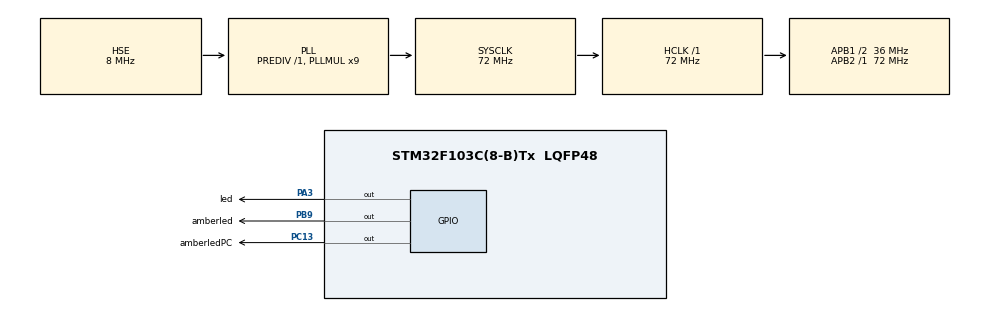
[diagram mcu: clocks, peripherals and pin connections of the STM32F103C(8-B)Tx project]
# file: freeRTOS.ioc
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FREERTOS.CountingSemaphores01=slotSemp,5,Dynamic,NULL;itemSemp,5,Dynamic,NULL
FREERTOS.Mutexes01=qMutex;mailMutex
FREERTOS.Queues01=itemQueue,5,int,NULL,Dynamic,NULL,NULL
FREERTOS.Tasks01=defaultTask,0,128,StartDefaultTask,Default,NULL,Dynamic,NULL,NULL;producer,-3,128,StartProducer,Default,NULL,Dynamic,NULL,NULL;consumer,-3,128,StartConsumer,Default,NULL,Dynamic,NULL,NULL
FREERTOS.configTOTAL_HEAP_SIZE=6144
FREERTOS.configUSE_COUNTING_SEMAPHORES=1
FREERTOS.configUSE_RECURSIVE_MUTEXES=1
FREERTOS.configUSE_TIMERS=1
Mcu.Family=STM32F1
Mcu.Name=STM32F103C(8-B)Tx
Mcu.Package=LQFP48
Mcu.UserConstants=Timer1_Counter,10000;TIM_RELOAD,10000;queueSize,10
NVIC.PriorityGroup=NVIC_PRIORITYGROUP_4
NVIC.TIM3_IRQn=true\:0\:0\:false\:false\:true\:false
NVIC.TimeBase=TIM3_IRQn
NVIC.TimeBaseIP=TIM3
PA13.Mode=Serial_Wire
PA13.Signal=SYS_JTMS-SWDIO
PA14.Mode=Serial_Wire
PA14.Signal=SYS_JTCK-SWCLK
PA3.GPIO_Label=led
PA3.PinState=GPIO_PIN_RESET
PA3.Signal=GPIO_Output
PB9.GPIO_Label=amberled
PB9.GPIO_Speed=GPIO_SPEED_FREQ_HIGH
PB9.PinState=GPIO_PIN_RESET
PB9.Signal=GPIO_Output
PC13-TAMPER-RTC.GPIO_Label=amberledPC
PC13-TAMPER-RTC.Signal=GPIO_Output
PD0-OSC_IN.Mode=HSE-External-Oscillator
PD0-OSC_IN.Signal=RCC_OSC_IN
PD1-OSC_OUT.Mode=HSE-External-Oscillator
PD1-OSC_OUT.Signal=RCC_OSC_OUT
ProjectManager.HeapSize=0x200
ProjectManager.StackSize=0x400
ProjectManager.TargetToolchain=SW4STM32
RCC.AHBFreq_Value=72000000
RCC.APB1CLKDivider=RCC_HCLK_DIV2
RCC.APB1Freq_Value=36000000
RCC.APB1TimFreq_Value=72000000
RCC.APB2Freq_Value=72000000
RCC.APB2TimFreq_Value=72000000
RCC.HCLKFreq_Value=72000000
RCC.PLLMUL=RCC_PLL_MUL9
RCC.PLLSourceVirtual=RCC_PLLSOURCE_HSE
RCC.SYSCLKFreq_VALUE=72000000
RCC.SYSCLKSource=RCC_SYSCLKSOURCE_PLLCLK
RCC.USBFreq_Value=72000000
VP_FREERTOS_VS_ENABLE.Mode=Enabled
VP_SYS_VS_tim3.Mode=TIM3
board=freeRTOS

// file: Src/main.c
/**
  ******************************************************************************
  * File Name          : main.c
  * Description        : Main program body
  ******************************************************************************
  * This notice applies to any and all portions of this file
  * that are not between comment pairs USER CODE BEGIN and
  * USER CODE END. Other portions of this file, whether
  * inserted by the user or by software development tools
  * are owned by their respective copyright owners.
  *
  * Copyright (c) 2017 STMicroelectronics International N.V.
  * All rights reserved.
  *
  * Redistribution and use in source and binary forms, with or without
  * modification, are permitted, provided that the following conditions are met:
  *
  * 1. Redistribution of source code must retain the above copyright notice,
  *    this list of conditions and the following disclaimer.
  * 2. Redistributions in binary form must reproduce the above copyright notice,
  *    this list of conditions and the following disclaimer in the documentation
  *    and/or other materials provided with the distribution.
  * 3. Neither the name of STMicroelectronics nor the names of other
  *    contributors to this software may be used to endorse or promote products
  *    derived from this software without specific written permission.
  * 4. This software, including modifications and/or derivative works of this
  *    software, must execute solely and exclusively on microcontroller or
  *    microprocessor devices manufactured by or for STMicroelectronics.
  * 5. Redistribution and use of this software other than as permitted under
  *    this license is void and will automatically terminate your rights under
  *    this license.
  *
  * THIS SOFTWARE IS PROVIDED BY STMICROELECTRONICS AND CONTRIBUTORS "AS IS"
  * AND ANY EXPRESS, IMPLIED OR STATUTORY WARRANTIES, INCLUDING, BUT NOT
  * LIMITED TO, THE IMPLIED WARRANTIES OF MERCHANTABILITY, FITNESS FOR A
  * PARTICULAR PURPOSE AND NON-INFRINGEMENT OF THIRD PARTY INTELLECTUAL PROPERTY
  * RIGHTS ARE DISCLAIMED TO THE FULLEST EXTENT PERMITTED BY LAW. IN NO EVENT
  * SHALL STMICROELECTRONICS OR CONTRIBUTORS BE LIABLE FOR ANY DIRECT, INDIRECT,
  * INCIDENTAL, SPECIAL, EXEMPLARY, OR CONSEQUENTIAL DAMAGES (INCLUDING, BUT NOT
  * LIMITED TO, PROCUREMENT OF SUBSTITUTE GOODS OR SERVICES; LOSS OF USE, DATA,
  * OR PROFITS; OR BUSINESS INTERRUPTION) HOWEVER CAUSED AND ON ANY THEORY OF
  * LIABILITY, WHETHER IN CONTRACT, STRICT LIABILITY, OR TORT (INCLUDING
  * NEGLIGENCE OR OTHERWISE) ARISING IN ANY WAY OUT OF THE USE OF THIS SOFTWARE,
  * EVEN IF ADVISED OF THE POSSIBILITY OF SUCH DAMAGE.
  *
  ******************************************************************************
  */
#include "main.h"
#include "stm32f1xx_hal.h"
#include "cmsis_os.h"

/* USER CODE BEGIN Includes */
#include <stdio.h>
/* USER CODE END Includes */

osThreadId defaultTaskHandle;
osThreadId producerHandle;
osThreadId consumerHandle;
osMessageQId itemQueueHandle;
osMutexId qMutexHandle;
osMutexId mailMutexHandle;
osSemaphoreId slotSempHandle;
osSemaphoreId itemSempHandle;

/* USER CODE BEGIN PV */
/* Private variables ---------------------------------------------------------*/
static uint32_t obj = 5;
osMailQId mailBoxHandler;

/* USER CODE END PV */

void SystemClock_Config(void);
static void MX_GPIO_Init(void);
extern void initialise_monitor_handles();
void StartDefaultTask(void const * argument);
void StartProducer(void const * argument);
void StartConsumer(void const * argument);

/* USER CODE BEGIN PFP */
/* Private function prototypes -----------------------------------------------*/
extern void initialise_monitor_handles(void);
/* USER CODE END PFP */

/* USER CODE BEGIN 0 */
typedef struct mail mailData;
struct mail{
	int data;
	char *name;
};
/* USER CODE END 0 */

int main(void)
{

  /* USER CODE BEGIN 1 */
  initialise_monitor_handles();

  /* USER CODE END 1 */

  /* MCU Configuration----------------------------------------------------------*/

  /* Reset of all peripherals, Initializes the Flash interface and the Systick. */
	HAL_Init();

  /* Configure the system clock */
  SystemClock_Config();

  /* Initialize all configured peripherals */
  MX_GPIO_Init();

  /* USER CODE BEGIN 2 */
  printf("Hello,Jason!\n");
  /* USER CODE END 2 */

  /* Create the mutex(es) */
  /* definition and creation of qMutex */
  osMutexDef(qMutex);
  qMutexHandle = osMutexCreate(osMutex(qMutex));

  /* definition and creation of mailMutex */
  osMutexDef(mailMutex);
  mailMutexHandle = osMutexCreate(osMutex(mailMutex));

  /* USER CODE BEGIN RTOS_MUTEX */
  osMailQDef(mailbox, 5, mailData);
  mailBoxHandler = osMailCreate(osMailQ(mailbox), NULL);

  /* add mutexes, ... */
  /* USER CODE END RTOS_MUTEX */

  /* Create the semaphores(s) */
  /* definition and creation of slotSemp */
  osSemaphoreDef(slotSemp);
  slotSempHandle = osSemaphoreCreate(osSemaphore(slotSemp), 5);

  /* definition and creation of itemSemp */
  osSemaphoreDef(itemSemp);
  itemSempHandle = osSemaphoreCreate(osSemaphore(itemSemp), 5);

  /* USER CODE BEGIN RTOS_SEMAPHORES */
  /* add semaphores, ... */

  slotSempHandle = xSemaphoreCreateCounting(5,5);
  itemSempHandle = xSemaphoreCreateCounting(5,0);
  /* USER CODE END RTOS_SEMAPHORES */

  /* Create the thread(s) */
  /* definition and creation of defaultTask */
  osThreadDef(defaultTask, StartDefaultTask, osPriorityNormal, 0, 128);
  defaultTaskHandle = osThreadCreate(osThread(defaultTask), NULL);

  /* definition and creation of producer */
  osThreadDef(producer, StartProducer, osPriorityIdle, 0, 128);
  producerHandle = osThreadCreate(osThread(producer), NULL);

  /* definition and creation of consumer */
  osThreadDef(consumer, StartConsumer, osPriorityIdle, 0, 128);
  consumerHandle = osThreadCreate(osThread(consumer), NULL);

  /* Create the queue(s) */
  /* definition and creation of itemQueue */
  osMessageQDef(itemQueue, 5, int);
  itemQueueHandle = osMessageCreate(osMessageQ(itemQueue), NULL);

  /* Start scheduler */
  osKernelStart();

  /* We should never get here as control is now taken by the scheduler */

  /* Infinite loop */
  /* USER CODE BEGIN WHILE */
/*
 * 	 osEvent  evt;
	 mailData *rxData;
 */
  while (1)
  {
  /* USER CODE END WHILE */

  /* USER CODE BEGIN 3 */

  //osMailGet(mailBoxHandler, portMAX_DELAY);

  }
  /* USER CODE END 3 */

}

/** System Clock Configuration
*/
void SystemClock_Config(void)
{

  RCC_OscInitTypeDef RCC_OscInitStruct;
  RCC_ClkInitTypeDef RCC_ClkInitStruct;

    /**Initializes the CPU, AHB and APB busses clocks
    */
  RCC_OscInitStruct.OscillatorType = RCC_OSCILLATORTYPE_HSE;
  RCC_OscInitStruct.HSEState = RCC_HSE_ON;
  RCC_OscInitStruct.HSEPredivValue = RCC_HSE_PREDIV_DIV1;
  RCC_OscInitStruct.HSIState = RCC_HSI_ON;
  RCC_OscInitStruct.PLL.PLLState = RCC_PLL_ON;
  RCC_OscInitStruct.PLL.PLLSource = RCC_PLLSOURCE_HSE;
  RCC_OscInitStruct.PLL.PLLMUL = RCC_PLL_MUL9;
  if (HAL_RCC_OscConfig(&RCC_OscInitStruct) != HAL_OK)
  {
    _Error_Handler(__FILE__, __LINE__);
  }

    /**Initializes the CPU, AHB and APB busses clocks
    */
  RCC_ClkInitStruct.ClockType = RCC_CLOCKTYPE_HCLK|RCC_CLOCKTYPE_SYSCLK
                              |RCC_CLOCKTYPE_PCLK1|RCC_CLOCKTYPE_PCLK2;
  RCC_ClkInitStruct.SYSCLKSource = RCC_SYSCLKSOURCE_PLLCLK;
  RCC_ClkInitStruct.AHBCLKDivider = RCC_SYSCLK_DIV1;
  RCC_ClkInitStruct.APB1CLKDivider = RCC_HCLK_DIV2;
  RCC_ClkInitStruct.APB2CLKDivider = RCC_HCLK_DIV1;

  if (HAL_RCC_ClockConfig(&RCC_ClkInitStruct, FLASH_LATENCY_2) != HAL_OK)
  {
    _Error_Handler(__FILE__, __LINE__);
  }

    /**Configure the Systick interrupt time
    */
  HAL_SYSTICK_Config(HAL_RCC_GetHCLKFreq()/1000);

    /**Configure the Systick
    */
  HAL_SYSTICK_CLKSourceConfig(SYSTICK_CLKSOURCE_HCLK);

  /* SysTick_IRQn interrupt configuration */
  HAL_NVIC_SetPriority(SysTick_IRQn, 15, 0);
}

/** Configure pins as
        * Analog
        * Input
        * Output
        * EVENT_OUT
        * EXTI
*/
static void MX_GPIO_Init(void)
{

  GPIO_InitTypeDef GPIO_InitStruct;

  /* GPIO Ports Clock Enable */
  __HAL_RCC_GPIOC_CLK_ENABLE();
  __HAL_RCC_GPIOD_CLK_ENABLE();
  __HAL_RCC_GPIOA_CLK_ENABLE();
  __HAL_RCC_GPIOB_CLK_ENABLE();

  /*Configure GPIO pin Output Level */
  HAL_GPIO_WritePin(amberledPC_GPIO_Port, amberledPC_Pin, GPIO_PIN_RESET);

  /*Configure GPIO pin Output Level */
  HAL_GPIO_WritePin(led_GPIO_Port, led_Pin, GPIO_PIN_RESET);

  /*Configure GPIO pin Output Level */
  HAL_GPIO_WritePin(amberled_GPIO_Port, amberled_Pin, GPIO_PIN_RESET);

  /*Configure GPIO pin : amberledPC_Pin */
  GPIO_InitStruct.Pin = amberledPC_Pin;
  GPIO_InitStruct.Mode = GPIO_MODE_OUTPUT_PP;
  GPIO_InitStruct.Speed = GPIO_SPEED_FREQ_LOW;
  HAL_GPIO_Init(amberledPC_GPIO_Port, &GPIO_InitStruct);

  /*Configure GPIO pin : led_Pin */
  GPIO_InitStruct.Pin = led_Pin;
  GPIO_InitStruct.Mode = GPIO_MODE_OUTPUT_PP;
  GPIO_InitStruct.Speed = GPIO_SPEED_FREQ_LOW;
  HAL_GPIO_Init(led_GPIO_Port, &GPIO_InitStruct);

  /*Configure GPIO pin : amberled_Pin */
  GPIO_InitStruct.Pin = amberled_Pin;
  GPIO_InitStruct.Mode = GPIO_MODE_OUTPUT_PP;
  GPIO_InitStruct.Speed = GPIO_SPEED_FREQ_HIGH;
  HAL_GPIO_Init(amberled_GPIO_Port, &GPIO_InitStruct);

}

/* StartDefaultTask function */
void StartDefaultTask(void const * argument)
{

  for(;;)
  {
    osDelay(1);
  }
}

/* StartProducer function */
void StartProducer(void const * argument)
{
  /* USER CODE BEGIN StartProducer */
	//mailData *data;
	//data = osMailAlloc(mailBoxHandler, osWaitForever);  // Allocate memory
  /* Infinite loop */
  for(;;)
  {
    xSemaphoreTake(slotSempHandle, portMAX_DELAY);
    osMutexWait(qMutexHandle, portMAX_DELAY);
    obj++;
    osMessagePut(itemQueueHandle, (uint32_t)obj, portMAX_DELAY);
	osMutexRelease(qMutexHandle);
	osMutexWait(qMutexHandle, portMAX_DELAY);
	if(osThreadGetId()==producerHandle){
		printf("Producer produce %lu\n",obj);
		osDelay(200);
	}
	osMutexRelease(qMutexHandle);
	xSemaphoreGive(itemSempHandle);

  }
  /* USER CODE END StartProducer */
}

/* StartConsumer function */
void StartConsumer(void const * argument)
{
  /* USER CODE BEGIN StartConsumer */
	//mailData *data;
  /* Infinite loop */
  osEvent mail;
  for(;;)
  {
     xSemaphoreTake(itemSempHandle, portMAX_DELAY);
	 osMutexWait(qMutexHandle, portMAX_DELAY);
  	 mail = osMessageGet(itemQueueHandle, portMAX_DELAY);
  	 osMutexRelease(qMutexHandle);
  	 osMutexWait(qMutexHandle, portMAX_DELAY);
  	 if(osThreadGetId()==consumerHandle){
  		printf("Consumer consume %lu\n",mail.value.v);
  		osDelay(200);
  	 }
  	 osMutexRelease(qMutexHandle);
  	 xSemaphoreGive(slotSempHandle);

  }
  /* USER CODE END StartConsumer */
}

void HAL_TIM_PeriodElapsedCallback(TIM_HandleTypeDef *htim)
{
  if (htim->Instance == TIM3) {
    HAL_IncTick();
  }
}

void _Error_Handler(char * file, int line)
{
  while(1)
  {
  }
}

/************************ (C) COPYRIGHT STMicroelectronics *****END OF FILE****/
